# ATSAMG51N18 device description
Architecture: CORTEX-M4; Family: SAMG; Series: SAMG51
Registers are 32-bit, access not given, no defined reset value unless marked. A register's access mark holds for its fields unless they carry their own. Offsets are from the block's base; [hi:lo] are bit positions.

## MEM2MEM — Memory to Memory
Instances: MEM2MEM 0x40028000
0x00 MEM2MEM_THR rw — Memory to Memory Transfer Holding Register
  [31:0] THDATA — Transfer Holding Data
0x04 MEM2MEM_MR rw — Memory to Memory Mode Register
  [1:0] TSIZE — Transfer Size
    0=T_8BIT (The buffer size is defined in byte.); 1=T_16BIT (The buffer size is defined in half-word (16-bit).); 2=T_32BIT (The buffer size is defined in word (32-bit). Default value.)
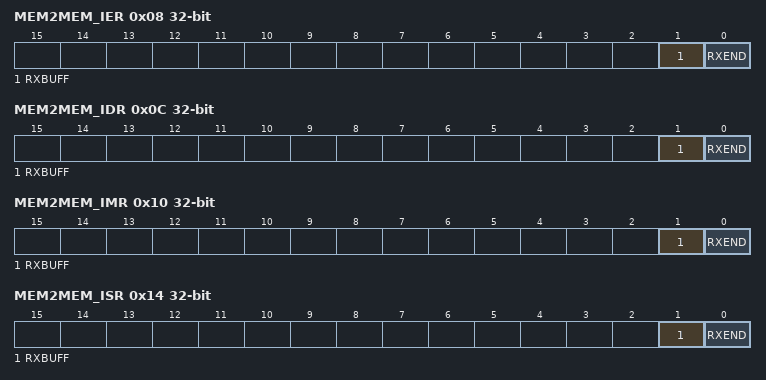
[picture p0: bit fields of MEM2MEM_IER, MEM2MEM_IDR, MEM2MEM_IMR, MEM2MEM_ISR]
0x08 MEM2MEM_IER wo (atomic set of MEM2MEM_IMR) — Memory to Memory Interrupt Enable Register
  [1] RXBUFF — Buffer Full Interrupt Enable
  [0] RXEND — End of Transfer Interrupt Enable
0x0C MEM2MEM_IDR wo (atomic clear of MEM2MEM_IMR) — Memory to Memory Interrupt Disable Register
  [1] RXBUFF — Buffer Full Interrupt Disable
  [0] RXEND — End of Transfer Interrupt Disable
0x10 MEM2MEM_IMR ro (atomic read) — Memory to Memory Interrupt Mask Register
  [1] RXBUFF — Buffer Full Interrupt Mask
  [0] RXEND — End of Transfer Interrupt Mask
0x14 MEM2MEM_ISR ro (atomic read) — Memory to Memory Interrupt Status Register
  [1] RXBUFF — Buffer Full
  [0] RXEND — End of Transfer
0x100 MEM2MEM_RPR rw — Receive Pointer Register
  [31:0] RXPTR
0x104 MEM2MEM_RCR rw — Receive Counter Register
  [15:0] RXCTR
0x108 MEM2MEM_TPR rw — Transmit Pointer Register
  [31:0] TXPTR — Transmit Counter Register
0x10C MEM2MEM_TCR rw — Transmit Counter Register
  [15:0] TXCTR
0x110 MEM2MEM_RNPR rw — Receive Next Pointer Register
  [31:0] RXNPTR — Receive Next Pointer
0x114 MEM2MEM_RNCR rw — Receive Next Counter Register
  [15:0] RXNCTR — Receive Next Counter
0x118 MEM2MEM_TNPR rw — Transmit Next Pointer Register
  [31:0] TXNPTR — Transmit Next Pointer
0x11C MEM2MEM_TNCR rw — Transmit Next Counter Register
  [15:0] TXNCTR — Transmit Counter Next
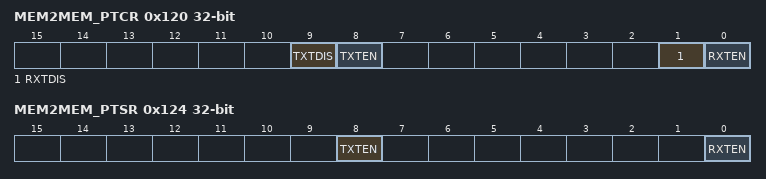
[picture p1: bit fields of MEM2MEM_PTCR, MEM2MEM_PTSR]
0x120 MEM2MEM_PTCR wo — Transfer Control Register
  [9] TXTDIS — Transmitter Transfer Disable
  [8] TXTEN — Transmitter Transfer Enable
  [1] RXTDIS — Receiver Transfer Disable
  [0] RXTEN — Receiver Transfer Enable
0x124 MEM2MEM_PTSR ro — Transfer Status Register
  [8] TXTEN — Transmitter Transfer Enable
  [0] RXTEN — Receiver Transfer Enable

## PDC — Peripheral DMA Controller
0x00 PERIPH_RPR rw — Receive Pointer Register
  [31:0] RXPTR
0x04 PERIPH_RCR rw — Receive Counter Register
  [15:0] RXCTR
0x08 PERIPH_TPR rw — Transmit Pointer Register
  [31:0] TXPTR — Transmit Counter Register
0x0C PERIPH_TCR rw — Transmit Counter Register
  [15:0] TXCTR
0x10 PERIPH_RNPR rw — Receive Next Pointer Register
  [31:0] RXNPTR — Receive Next Pointer
0x14 PERIPH_RNCR rw — Receive Next Counter Register
  [15:0] RXNCTR — Receive Next Counter
0x18 PERIPH_TNPR rw — Transmit Next Pointer Register
  [31:0] TXNPTR — Transmit Next Pointer
0x1C PERIPH_TNCR rw — Transmit Next Counter Register
  [15:0] TXNCTR — Transmit Counter Next
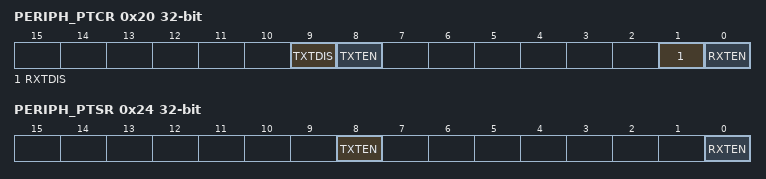
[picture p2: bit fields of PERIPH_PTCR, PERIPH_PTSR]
0x20 PERIPH_PTCR wo — Transfer Control Register
  [9] TXTDIS — Transmitter Transfer Disable
  [8] TXTEN — Transmitter Transfer Enable
  [1] RXTDIS — Receiver Transfer Disable
  [0] RXTEN — Receiver Transfer Enable
0x24 PERIPH_PTSR ro — Transfer Status Register
  [8] TXTEN — Transmitter Transfer Enable
  [0] RXTEN — Receiver Transfer Enable

## RSTC — Reset Controller
Instances: RSTC 0x400E1400
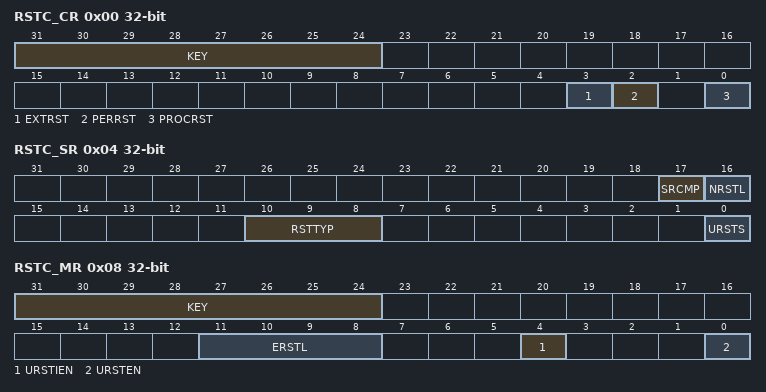
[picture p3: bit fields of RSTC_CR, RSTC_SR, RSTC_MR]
0x00 RSTC_CR wo — Control Register
  [31:24] KEY — System Reset Key
    165=PASSWD (Writing any other value in this field aborts the write operation.)
  [3] EXTRST — External Reset
  [2] PERRST — Peripheral Reset
  [0] PROCRST — Processor Reset
0x04 RSTC_SR ro — Status Register
  [17] SRCMP — Software Reset Command in Progress
  [16] NRSTL — NRST Pin Level
  [10:8] RSTTYP — Reset Type
    0=GENERAL_RST (First power-up reset); 2=WDT_RST (Watchdog fault occurred); 3=SOFT_RST (Processor reset required by the software); 4=USER_RST (NRST pin detected low)
  [0] URSTS — User Reset Status
0x08 RSTC_MR rw — Mode Register
  [31:24] KEY — Write Access Password
    165=PASSWD (Writing any other value in this field aborts the write operation.Always reads as 0.)
  [11:8] ERSTL — External Reset Length
  [4] URSTIEN — User Reset Interrupt Enable
  [0] URSTEN — User Reset Enable

## Notices in the file
Copyright (c) 2017 Microchip Technology Inc.
SPDX-License-Identifier: Apache-2.0
Licensed under the Apache License, Version 2.0 (the "License");
you may not use this file except in compliance with the License.
You may obtain a copy of the License at
http://www.apache.org/licenses/LICENSE-2.0
Unless required by applicable law or agreed to in writing, software
distributed under the License is distributed on an "AS IS" BASIS,
WITHOUT WARRANTIES OR CONDITIONS OF ANY KIND, either express or implied.
See the License for the specific language governing permissions and
limitations under the License.
